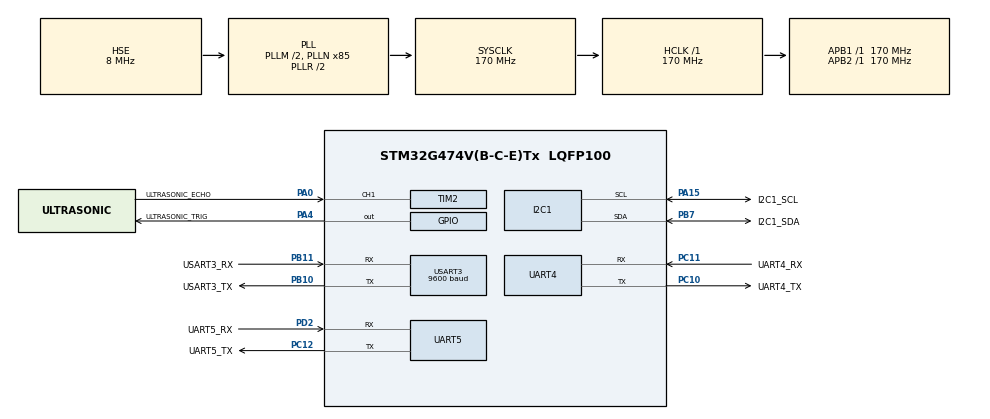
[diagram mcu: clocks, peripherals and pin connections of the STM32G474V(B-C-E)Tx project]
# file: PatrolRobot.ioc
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I2C1.Timing=0x40B285C2
Mcu.Family=STM32G4
Mcu.Name=STM32G474V(B-C-E)Tx
Mcu.Package=LQFP100
NVIC.PriorityGroup=NVIC_PRIORITYGROUP_4
NVIC.TIM2_IRQn=true\:6\:0\:false\:false\:true\:true\:true\:true
NVIC.UART4_IRQn=true\:7\:0\:false\:false\:true\:true\:true\:true
NVIC.UART5_IRQn=true\:0\:0\:false\:false\:true\:true\:true\:true
NVIC.USART3_IRQn=true\:5\:0\:false\:false\:true\:true\:true\:true
PA0.GPIO_Label=ULTRASONIC_ECHO
PA0.Signal=S_TIM2_CH1
PA15.GPIO_Label=I2C1_SCL
PA15.Mode=I2C
PA15.Signal=I2C1_SCL
PA4.GPIO_Label=ULTRASONIC_TRIG
PA4.PinState=GPIO_PIN_RESET
PA4.Signal=GPIO_Output
PB10.GPIO_Label=USART3_TX
PB10.Mode=Asynchronous
PB10.Signal=USART3_TX
PB11.GPIO_Label=USART3_RX
PB11.Mode=Asynchronous
PB11.Signal=USART3_RX
PB7.GPIO_Label=I2C1_SDA
PB7.Mode=I2C
PB7.Signal=I2C1_SDA
PC10.GPIO_Label=UART4_TX
PC10.Mode=Asynchronous
PC10.Signal=UART4_TX
PC11.GPIO_Label=UART4_RX
PC11.Mode=Asynchronous
PC11.Signal=UART4_RX
PC12.GPIO_Label=UART5_TX
PC12.Mode=Asynchronous
PC12.Signal=UART5_TX
PD2.GPIO_Label=UART5_RX
PD2.Mode=Asynchronous
PD2.Signal=UART5_RX
PF0-OSC_IN.Mode=HSE-External-Oscillator
PF0-OSC_IN.Signal=RCC_OSC_IN
PF1-OSC_OUT.Mode=HSE-External-Oscillator
PF1-OSC_OUT.Signal=RCC_OSC_OUT
ProjectManager.HeapSize=0x200
ProjectManager.StackSize=0x400
ProjectManager.TargetToolchain=MDK-ARM V5.32
RCC.ADC12Freq_Value=170000000
RCC.ADC345Freq_Value=170000000
RCC.AHBFreq_Value=170000000
RCC.APB1Freq_Value=170000000
RCC.APB1TimFreq_Value=170000000
RCC.APB2Freq_Value=170000000
RCC.APB2TimFreq_Value=170000000
RCC.CortexFreq_Value=170000000
RCC.EXTERNAL_CLOCK_VALUE=12288000
RCC.HCLKFreq_Value=170000000
RCC.HSE_VALUE=8000000
RCC.HSI48_VALUE=48000000
RCC.HSI_VALUE=16000000
RCC.LSE_VALUE=32768
RCC.PLLM=RCC_PLLM_DIV2
RCC.PLLN=85
RCC.PLLSourceVirtual=RCC_PLLSOURCE_HSE
RCC.SYSCLKFreq_VALUE=170000000
RCC.SYSCLKSource=RCC_SYSCLKSOURCE_PLLCLK
RCC.USBFreq_Value=170000000
RCC.VCOOutputFreq_Value=340000000
SH.S_TIM2_CH1.0=TIM2_CH1,Input_Capture1_from_TI1
TIM2.AutoReloadPreload=TIM_AUTORELOAD_PRELOAD_DISABLE
TIM2.Channel-Input_Capture1_from_TI1=TIM_CHANNEL_1
TIM2.ClockDivision=TIM_CLOCKDIVISION_DIV1
TIM2.CounterMode=TIM_COUNTERMODE_UP
TIM2.ICFilter_CH1=0
TIM2.ICPolarity_CH1=TIM_INPUTCHANNELPOLARITY_RISING
TIM2.ICPrescaler-Input_Capture1_from_TI1=TIM_ICPSC_DIV1
TIM2.ICSelection-Input_Capture1_from_TI1=TIM_ICSELECTION_DIRECTTI
TIM2.Period=0xFFFFFFFF
TIM2.Prescaler=169
TIM2.TIM_MasterOutputTrigger=TIM_TRGO_RESET
TIM2.TIM_MasterSlaveMode=TIM_MASTERSLAVEMODE_DISABLE
UART4.VirtualMode-Asynchronous=VM_ASYNC
USART3.BaudRate=9600
USART3.VirtualMode-Asynchronous=VM_ASYNC
VP_SYS_VS_DBSignals.Mode=DisableDeadBatterySignals
VP_TIM2_VS_ClockSourceINT.Mode=Internal
board=custom

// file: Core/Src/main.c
/* USER CODE BEGIN Header */
/**
  ******************************************************************************
  * @file           : main.c
  * @brief          : Main program body
  ******************************************************************************
  * @attention
  *
  * Copyright (c) 2026 STMicroelectronics.
  * All rights reserved.
  *
  * This software is licensed under terms that can be found in the LICENSE file
  * in the root directory of this software component.
  * If no LICENSE file comes with this software, it is provided AS-IS.
  *
  ******************************************************************************
  */
/* USER CODE END Header */
#include "main.h"
#include "i2c.h"
#include "tim.h"
#include "usart.h"
#include "gpio.h"

/* USER CODE BEGIN Includes */
#include "patrol_robot_app.h"
/* USER CODE END Includes */

void SystemClock_Config(void);

int main(void)
{

  /* MCU Configuration--------------------------------------------------------*/

  /* Reset of all peripherals, Initializes the Flash interface and the Systick. */
  HAL_Init();

  /* Configure the system clock */
  SystemClock_Config();

  /* Initialize all configured peripherals */
  MX_GPIO_Init();
  MX_TIM2_Init();
  MX_UART4_Init();
  MX_UART5_Init();
  MX_USART3_UART_Init();
  MX_I2C1_Init();
  /* USER CODE BEGIN 2 */
  /* 所有底层外设初始化完成后，再初始化传感器、蓝牙和应用调度状态。 */
  PatrolRobotApp_Init();
  /* USER CODE END 2 */

  /* Infinite loop */
  while (1)
  {

    /* USER CODE BEGIN 3 */
    /* 非阻塞执行传感器采样、命令处理和 BLE 遥测状态机。 */
    PatrolRobotApp_Process();
  }
  /* USER CODE END 3 */
}

void SystemClock_Config(void)
{
  RCC_OscInitTypeDef RCC_OscInitStruct = {0};
  RCC_ClkInitTypeDef RCC_ClkInitStruct = {0};

  /** Configure the main internal regulator output voltage
  */
  HAL_PWREx_ControlVoltageScaling(PWR_REGULATOR_VOLTAGE_SCALE1_BOOST);

  /** Initializes the RCC Oscillators according to the specified parameters
  * in the RCC_OscInitTypeDef structure.
  */
  RCC_OscInitStruct.OscillatorType = RCC_OSCILLATORTYPE_HSE;
  RCC_OscInitStruct.HSEState = RCC_HSE_ON;
  RCC_OscInitStruct.PLL.PLLState = RCC_PLL_ON;
  RCC_OscInitStruct.PLL.PLLSource = RCC_PLLSOURCE_HSE;
  RCC_OscInitStruct.PLL.PLLM = RCC_PLLM_DIV2;
  RCC_OscInitStruct.PLL.PLLN = 85;
  RCC_OscInitStruct.PLL.PLLP = RCC_PLLP_DIV2;
  RCC_OscInitStruct.PLL.PLLQ = RCC_PLLQ_DIV2;
  RCC_OscInitStruct.PLL.PLLR = RCC_PLLR_DIV2;
  if (HAL_RCC_OscConfig(&RCC_OscInitStruct) != HAL_OK)
  {
    Error_Handler();
  }

  /** Initializes the CPU, AHB and APB buses clocks
  */
  RCC_ClkInitStruct.ClockType = RCC_CLOCKTYPE_HCLK|RCC_CLOCKTYPE_SYSCLK
                              |RCC_CLOCKTYPE_PCLK1|RCC_CLOCKTYPE_PCLK2;
  RCC_ClkInitStruct.SYSCLKSource = RCC_SYSCLKSOURCE_PLLCLK;
  RCC_ClkInitStruct.AHBCLKDivider = RCC_SYSCLK_DIV1;
  RCC_ClkInitStruct.APB1CLKDivider = RCC_HCLK_DIV1;
  RCC_ClkInitStruct.APB2CLKDivider = RCC_HCLK_DIV1;

  if (HAL_RCC_ClockConfig(&RCC_ClkInitStruct, FLASH_LATENCY_4) != HAL_OK)
  {
    Error_Handler();
  }
}

/* USER CODE BEGIN 4 */
void HAL_UART_RxCpltCallback(UART_HandleTypeDef *huart)
{
  /* HAL 回调仅转发事件，具体处理由应用层和 BSP 完成。 */
  PatrolRobotApp_NotifyUartRxComplete(huart);
}

void HAL_UARTEx_RxEventCallback(UART_HandleTypeDef *huart, uint16_t Size)
{
  /* Wi-Fi 驱动在主循环解析数据，中断回调只转存接收块。 */
  PatrolRobotApp_NotifyUartRxEvent(huart, Size);
}

void HAL_UART_ErrorCallback(UART_HandleTypeDef *huart)
{
  PatrolRobotApp_NotifyUartError(huart);
}

void HAL_TIM_IC_CaptureCallback(TIM_HandleTypeDef *htim)
{
  PatrolRobotApp_NotifyTimInputCapture(htim);
}

/* USER CODE END 4 */

void Error_Handler(void)
{
  __disable_irq();
  while (1)
  {
  }
}
